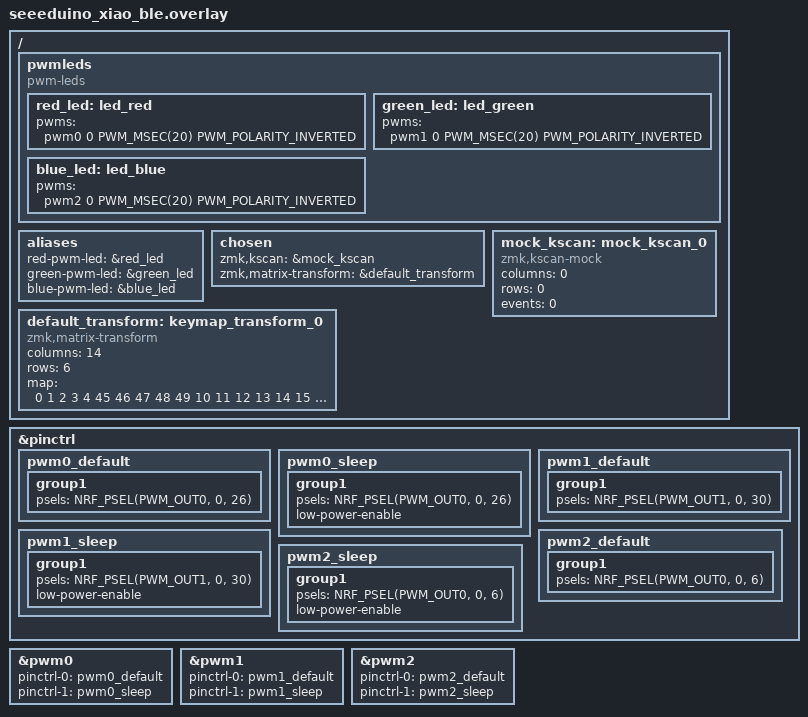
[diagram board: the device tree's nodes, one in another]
/ {
    pwmleds {
        compatible = "pwm-leds";
        red_led: led_red {
            pwms = <&pwm0 0 PWM_MSEC(20) PWM_POLARITY_INVERTED>;
        };
        green_led: led_green {
            pwms = <&pwm1 0 PWM_MSEC(20) PWM_POLARITY_INVERTED>;
        };
        blue_led: led_blue {
            pwms = <&pwm2 0 PWM_MSEC(20) PWM_POLARITY_INVERTED>;
        };
    };

    aliases {
        red-pwm-led = &red_led;
        green-pwm-led = &green_led;
        blue-pwm-led = &blue_led;
    };

    chosen {
        zmk,kscan = &mock_kscan;
        zmk,matrix-transform = &default_transform;
    };

    mock_kscan: mock_kscan_0 {
        compatible = "zmk,kscan-mock";
        columns = <0>;
        rows = <0>;
        events = <0>;
    };

    default_transform: keymap_transform_0 {
        compatible = "zmk,matrix-transform";
        columns = <14>;
        rows = <6>;
        map = <
             0  1  2  3  4                                          45 46 47 48 49
            10 11 12 13 14 15                                    44 50 51 52 53 54
            20 21 22 23 24 25                                    43 55 56 57 58 59
            30 31 32 33 34 35                                    42 60 61 62 63 64
            40 41 42 43 44 45                                    41 65 66 67 68 69
            70 71 72 73 74                                          75 76 77 78 79
                                   5  6  7  8  9 10
                                  35 36 37 38 39 40
        >;
    };
};

&pinctrl {
    pwm0_default: pwm0_default {
        group1 {
            psels = <NRF_PSEL(PWM_OUT0, 0, 26)>;  // Red LED - PWM0 channel 0
        };
    };

    pwm0_sleep: pwm0_sleep {
        group1 {
            psels = <NRF_PSEL(PWM_OUT0, 0, 26)>;
            low-power-enable;
        };
    };

    pwm1_default: pwm1_default {
        group1 {
            psels = <NRF_PSEL(PWM_OUT1, 0, 30)>;  // Green LED - PWM1 channel 1
        };
    };

    pwm1_sleep: pwm1_sleep {
        group1 {
            psels = <NRF_PSEL(PWM_OUT1, 0, 30)>;
            low-power-enable;
        };
    };

    pwm2_default: pwm2_default {
        group1 {
            psels = <NRF_PSEL(PWM_OUT0, 0, 6)>;   // Blue LED
        };
    };

    pwm2_sleep: pwm2_sleep {
        group1 {
            psels = <NRF_PSEL(PWM_OUT0, 0, 6)>;
            low-power-enable;
        };
    };
};

&pwm0 {
    status = "okay";
    pinctrl-0 = <&pwm0_default>;
    pinctrl-1 = <&pwm0_sleep>;
    pinctrl-names = "default", "sleep";
};

&pwm1 {
    status = "okay";
    pinctrl-0 = <&pwm1_default>;
    pinctrl-1 = <&pwm1_sleep>;
    pinctrl-names = "default", "sleep";
};

&pwm2 {
    status = "okay";
    pinctrl-0 = <&pwm2_default>;
    pinctrl-1 = <&pwm2_sleep>;
    pinctrl-names = "default", "sleep";
};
